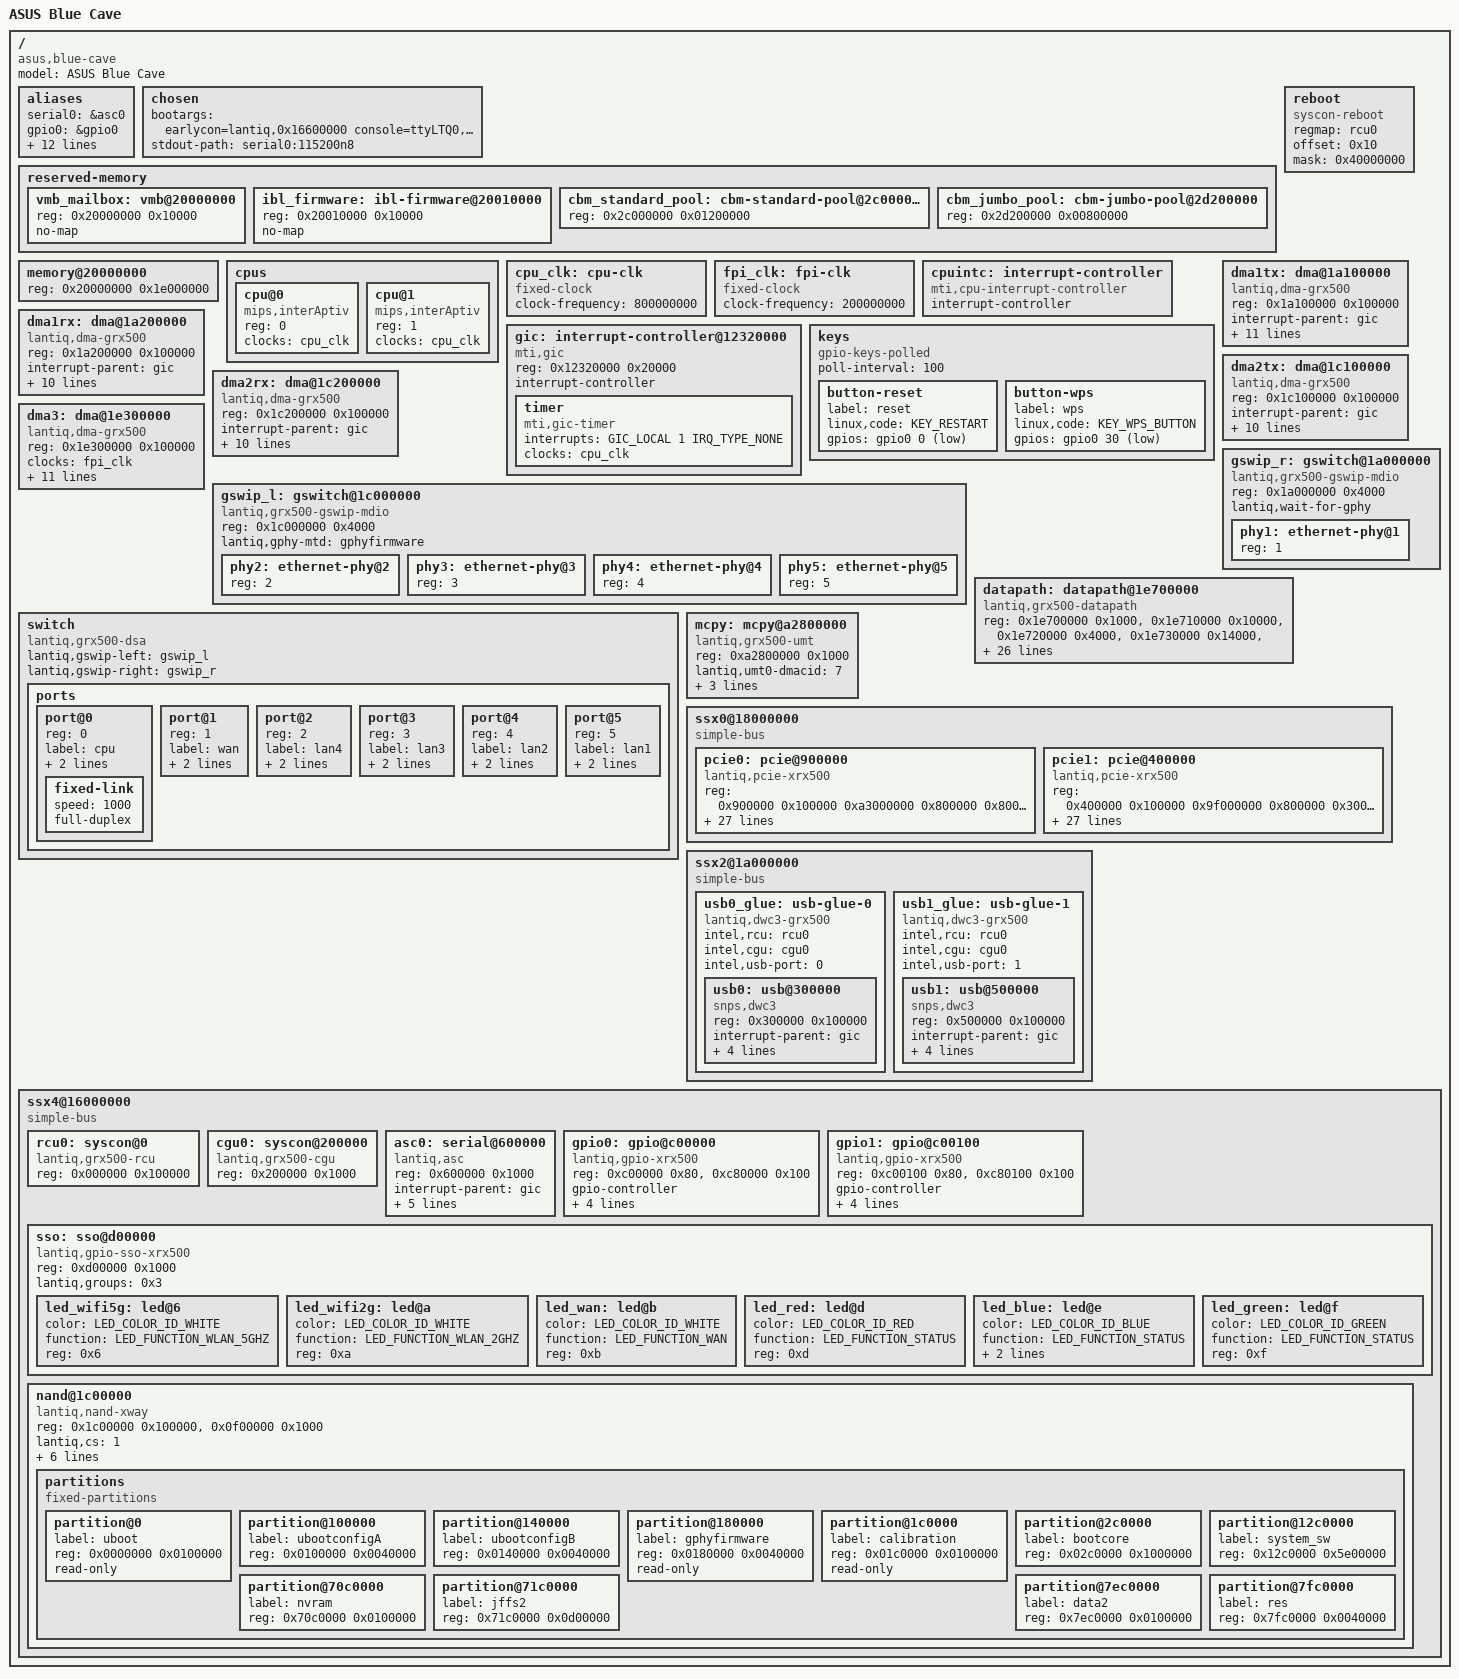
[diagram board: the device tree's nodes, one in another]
// SPDX-License-Identifier: GPL-2.0-or-later
/*
 * ASUS Blue Cave (Intel/Lantiq GRX350 / xRX500)
 * Stage-2 Bring-up DTS (Linux 6.18 + UART + Reboot + NAND 128MiB + USB 3.0 xHCI)
 */

/dts-v1/;

#include <dt-bindings/gpio/gpio.h>
#include <dt-bindings/input/input.h>
#include <dt-bindings/interrupt-controller/mips-gic.h>
#include <dt-bindings/leds/common.h>

/ {
	compatible = "asus,blue-cave", "intel,grx500", "lantiq,xrx500";
	model = "ASUS Blue Cave";
	#address-cells = <1>;
	#size-cells = <1>;

	aliases {
		serial0 = &asc0;
		gpio0 = &gpio0;
		gpio1 = &gpio1;
		dma1 = &dma1tx;
		dma2 = &dma1rx;
		dma3 = &dma2tx;
		dma4 = &dma2rx;
		dma5 = &dma3;
		pcie0 = &pcie0;
		pcie1 = &pcie1;
		led-boot = &led_blue;
		led-failsafe = &led_red;
		led-running = &led_blue;
		led-upgrade = &led_green;
	};

	chosen {
		bootargs = "earlycon=lantiq,0x16600000 console=ttyLTQ0,115200 clk_ignore_unused panic=5";
		stdout-path = "serial0:115200n8";
	};

	reserved-memory {
		#address-cells = <1>;
		#size-cells = <1>;
		ranges;

		vmb_mailbox: vmb@20000000 {
			reg = <0x20000000 0x10000>;
			no-map;
		};

		ibl_firmware: ibl-firmware@20010000 {
			reg = <0x20010000 0x10000>;
			no-map;
		};

		cbm_standard_pool: cbm-standard-pool@2c000000 {
			reg = <0x2c000000 0x01200000>;
		};

		cbm_jumbo_pool: cbm-jumbo-pool@2d200000 {
			reg = <0x2d200000 0x00800000>;
		};
	};

	/*
	 * GRX350 physical DRAM: 480 MiB (0x1e000000) @ 0x20000000 via EVA 1GB
	 */
	memory@20000000 {
		device_type = "memory";
		reg = <0x20000000 0x1e000000>;
	};

	cpus {
		#address-cells = <1>;
		#size-cells = <0>;

		cpu@0 {
			device_type = "cpu";
			compatible = "mips,interAptiv";
			reg = <0>;
			clocks = <&cpu_clk>;
		};

		cpu@1 {
			device_type = "cpu";
			compatible = "mips,interAptiv";
			reg = <1>;
			clocks = <&cpu_clk>;
		};
	};

	cpu_clk: cpu-clk {
		compatible = "fixed-clock";
		#clock-cells = <0>;
		clock-frequency = <800000000>;
	};

	fpi_clk: fpi-clk {
		compatible = "fixed-clock";
		#clock-cells = <0>;
		clock-frequency = <200000000>;
	};

	cpuintc: interrupt-controller {
		#interrupt-cells = <1>;
		interrupt-controller;
		compatible = "mti,cpu-interrupt-controller";
	};

	gic: interrupt-controller@12320000 {
		compatible = "mti,gic";
		reg = <0x12320000 0x20000>;

		interrupt-controller;
		#interrupt-cells = <3>;

		timer {
			compatible = "mti,gic-timer";
			interrupts = <GIC_LOCAL 1 IRQ_TYPE_NONE>;
			clocks = <&cpu_clk>;
		};
	};

	reboot {
		compatible = "syscon-reboot";
		regmap = <&rcu0>;
		offset = <0x10>;
		mask = <0x40000000>;
	};

	keys {
		compatible = "gpio-keys-polled";
		poll-interval = <100>;

		button-reset {
			label = "reset";
			linux,code = <KEY_RESTART>;
			gpios = <&gpio0 0 GPIO_ACTIVE_LOW>;
		};

		button-wps {
			label = "wps";
			linux,code = <KEY_WPS_BUTTON>;
			gpios = <&gpio0 30 GPIO_ACTIVE_LOW>;
		};
	};

	/* GRX350/GRX500 DMA controllers for GSWIP-L/R & CBM */
	dma1tx: dma@1a100000 {
		compatible = "lantiq,dma-grx500";
		reg = <0x1a100000 0x100000>;
		interrupt-parent = <&gic>;
		interrupts = <GIC_SHARED 65 IRQ_TYPE_LEVEL_HIGH>;
		lantiq,dma-pkt-arb = <2>;
		lantiq,dma-burst = <16>;
		lantiq,dma-polling-cnt = <108>;
		lantiq,dma-chan-fc = <1>;
		lantiq,dma-desc-fod = <1>;
		lantiq,dma-desc-in-sram = <1>;
		lantiq,dma-drb = <0>;
		lantiq,dma-byte-en = <1>;
		lantiq,budget = <20>;
		lantiq,dma-lab-cnt = <2>;
		status = "okay";
	};

	dma1rx: dma@1a200000 {
		compatible = "lantiq,dma-grx500";
		reg = <0x1a200000 0x100000>;
		interrupt-parent = <&gic>;
		interrupts = <GIC_SHARED 66 IRQ_TYPE_LEVEL_HIGH>;
		lantiq,dma-pkt-arb = <2>;
		lantiq,dma-burst = <16>;
		lantiq,dma-polling-cnt = <24>;
		lantiq,dma-chan-fc = <0>;
		lantiq,dma-desc-fod = <1>;
		lantiq,dma-desc-in-sram = <0>;
		lantiq,dma-drb = <0>;
		lantiq,dma-byte-en = <0>;
		lantiq,budget = <20>;
		status = "okay";
	};

	dma2tx: dma@1c100000 {
		compatible = "lantiq,dma-grx500";
		reg = <0x1c100000 0x100000>;
		interrupt-parent = <&gic>;
		interrupts = <GIC_SHARED 67 IRQ_TYPE_LEVEL_HIGH>;
		lantiq,dma-pkt-arb = <2>;
		lantiq,dma-burst = <16>;
		lantiq,dma-polling-cnt = <24>;
		lantiq,dma-chan-fc = <1>;
		lantiq,dma-desc-fod = <1>;
		lantiq,dma-desc-in-sram = <0>;
		lantiq,dma-drb = <0>;
		lantiq,dma-byte-en = <1>;
		lantiq,budget = <20>;
		status = "okay";
	};

	dma2rx: dma@1c200000 {
		compatible = "lantiq,dma-grx500";
		reg = <0x1c200000 0x100000>;
		interrupt-parent = <&gic>;
		interrupts = <GIC_SHARED 68 IRQ_TYPE_LEVEL_HIGH>;
		lantiq,dma-pkt-arb = <2>;
		lantiq,dma-burst = <16>;
		lantiq,dma-polling-cnt = <24>;
		lantiq,dma-chan-fc = <0>;
		lantiq,dma-desc-fod = <1>;
		lantiq,dma-desc-in-sram = <1>;
		lantiq,dma-drb = <0>;
		lantiq,dma-byte-en = <1>;
		lantiq,budget = <20>;
		status = "okay";
	};

	dma3: dma@1e300000 {
		compatible = "lantiq,dma-grx500";
		reg = <0x1e300000 0x100000>;
		clocks = <&fpi_clk>;
		interrupt-parent = <&gic>;
		interrupts = <GIC_SHARED 77 IRQ_TYPE_LEVEL_HIGH>;
		lantiq,dma-pkt-arb = <2>;
		lantiq,dma-burst = <16>;
		lantiq,dma-polling-cnt = <24>;
		lantiq,dma-chan-fc = <0>;
		lantiq,dma-desc-fod = <0>;
		lantiq,dma-desc-in-sram = <1>;
		lantiq,dma-drb = <0>;
		lantiq,dma-byte-en = <1>;
		lantiq,budget = <20>;
		status = "okay";
	};

	/* GSWIP-L MDIO (loads GPHY FW directly from factory NAND mtd3 at runtime) */
	gswip_l: gswitch@1c000000 {
		compatible = "lantiq,grx500-gswip-mdio";
		reg = <0x1c000000 0x4000>;
		lantiq,gphy-mtd = "gphyfirmware";
		#address-cells = <1>;
		#size-cells = <0>;

		phy2: ethernet-phy@2 { reg = <2>; };
		phy3: ethernet-phy@3 { reg = <3>; };
		phy4: ethernet-phy@4 { reg = <4>; };
		phy5: ethernet-phy@5 { reg = <5>; };
	};

	/* GSWIP-R MDIO (WAN port) */
	gswip_r: gswitch@1a000000 {
		compatible = "lantiq,grx500-gswip-mdio";
		reg = <0x1a000000 0x4000>;
		lantiq,wait-for-gphy;
		#address-cells = <1>;
		#size-cells = <0>;

		phy1: ethernet-phy@1 { reg = <1>; };
	};

	datapath: datapath@1e700000 {
		compatible = "lantiq,grx500-datapath";
		reg = <0x1e700000 0x1000>,
		      <0x1e710000 0x10000>,
		      <0x1e720000 0x4000>,
		      <0x1e730000 0x14000>,
		      <0x1e750000 0x400>,
		      <0x1e750800 0x400>,
		      <0x1e760000 0x10000>,
		      <0x1e780000 0x20000>,
		      <0x1e7c0000 0x30000>,
		      <0x1e800000 0x100000>,
		      <0x1e900000 0x100000>,
		      <0x1e500000 0x100000>;
		reg-names = "tmu", "cbm", "qidt", "sbim", "qeqcnt",
			    "qdqcnt", "ls", "eqm", "dqm", "fsqm0",
			    "fsqm1", "dma-desc";
		interrupt-parent = <&gic>;
		interrupts = <GIC_SHARED 174 IRQ_TYPE_LEVEL_HIGH>,
			     <GIC_SHARED 178 IRQ_TYPE_LEVEL_HIGH>,
			     <GIC_SHARED 179 IRQ_TYPE_LEVEL_HIGH>,
			     <GIC_SHARED 180 IRQ_TYPE_LEVEL_HIGH>,
			     <GIC_SHARED 181 IRQ_TYPE_LEVEL_HIGH>;
		interrupt-names = "eqm", "dqm-cpu0", "dqm-cpu1",
				  "dqm-cpu2", "dqm-cpu3";
		lantiq,gswip-left = <&gswip_l>;
		lantiq,gswip-right = <&gswip_r>;
		memory-region = <&cbm_standard_pool>, <&cbm_jumbo_pool>;
		memory-region-names = "standard", "jumbo";
		lantiq,lan-eqm-routes = <5 2 14 0 2>, <5 2 30 1 2>,
				 <6 2 15 0 2>, <6 2 31 1 2>;
		lantiq,gswr-eqm-route = <7 1 0 0 2>;
		lantiq,lan-dqm-routes = <6 16 2 1 2>, <7 17 2 2 2>,
				 <8 18 2 3 2>, <9 19 2 4 2>,
				 <10 20 2 5 2>, <11 21 2 6 2>,
				 <12 22 2 9 2>, <13 23 2 10 2>,
				 <14 24 2 11 2>, <15 25 2 12 2>,
				 <16 26 2 13 2>, <17 27 2 14 2>;
		lantiq,wan-dqm-route = <19 28 1 15 2>;
		lantiq,cpu-dqm-port = <2 35>;
	};

	switch {
		compatible = "lantiq,grx500-dsa";
		lantiq,gswip-left = <&gswip_l>;
		lantiq,gswip-right = <&gswip_r>;

		ports {
			#address-cells = <1>;
			#size-cells = <0>;

			port@0 {
				reg = <0>;
				label = "cpu";
				ethernet = <&datapath>;
				phy-mode = "internal";

				fixed-link {
					speed = <1000>;
					full-duplex;
				};
			};

			port@1 {
				reg = <1>;
				label = "wan";
				phy-mode = "rgmii";
				phy-handle = <&phy1>;
			};

			port@2 {
				reg = <2>;
				label = "lan4";
				phy-mode = "gmii";
				phy-handle = <&phy2>;
			};

			port@3 {
				reg = <3>;
				label = "lan3";
				phy-mode = "gmii";
				phy-handle = <&phy3>;
			};

			port@4 {
				reg = <4>;
				label = "lan2";
				phy-mode = "gmii";
				phy-handle = <&phy4>;
			};

			port@5 {
				reg = <5>;
				label = "lan1";
				phy-mode = "gmii";
				phy-handle = <&phy5>;
			};
		};
	};

	mcpy: mcpy@a2800000 {
		compatible = "lantiq,grx500-umt";
		reg = <0xa2800000 0x1000>;
		lantiq,umt0-dmacid = <7>;
		lantiq,umt1-dmacid = <8>;
		lantiq,umt2-dmacid = <9>;
		lantiq,umt3-dmacid = <10>;
	};

	/* SSX0: PCIe Root Complexes (pcie0 & pcie1 for WAV514/524 dual Wi-Fi) */
	ssx0@18000000 {
		compatible = "simple-bus";
		#address-cells = <1>;
		#size-cells = <1>;
		ranges = <0x0 0x18000000 0xa8000000>;

		pcie0: pcie@900000 {
			compatible = "lantiq,pcie-xrx500";
			device_type = "pci";
			#address-cells = <3>;
			#size-cells = <2>;
			reg = <
				0x900000 0x100000
				0xa3000000 0x800000
				0x800000 0x100000
				0x500000 0x100000
				0x600000 0x100000
				0x700000 0x100000
			>;
			reg-names = "csr", "cfg", "app", "phy", "msi", "pic";
			interrupt-parent = <&gic>;
			interrupt-controller;
			interrupts = <GIC_SHARED 128 IRQ_TYPE_EDGE_RISING>,
				     <GIC_SHARED 129 IRQ_TYPE_EDGE_RISING>,
				     <GIC_SHARED 130 IRQ_TYPE_EDGE_RISING>,
				     <GIC_SHARED 131 IRQ_TYPE_EDGE_RISING>,
				     <GIC_SHARED 132 IRQ_TYPE_EDGE_RISING>,
				     <GIC_SHARED 133 IRQ_TYPE_EDGE_RISING>,
				     <GIC_SHARED 134 IRQ_TYPE_EDGE_RISING>,
				     <GIC_SHARED 135 IRQ_TYPE_EDGE_RISING>,
				     <GIC_SHARED 152 IRQ_TYPE_LEVEL_HIGH>,
				     <GIC_SHARED 136 IRQ_TYPE_LEVEL_HIGH>,
				     <GIC_SHARED 137 IRQ_TYPE_LEVEL_HIGH>,
				     <GIC_SHARED 138 IRQ_TYPE_LEVEL_HIGH>,
				     <GIC_SHARED 139 IRQ_TYPE_LEVEL_HIGH>;
			interrupt-names = "msi0", "msi1", "msi2", "msi3",
					  "msi4", "msi5", "msi6", "msi7",
					  "ir", "inta", "intb", "intc", "intd";
			#interrupt-cells = <1>;
			interrupt-map-mask = <0 0 0 0x7>;
			interrupt-map = <0 0 0 1 &pcie0 0>,
					<0 0 0 2 &pcie0 1>,
					<0 0 0 3 &pcie0 2>,
					<0 0 0 4 &pcie0 3>;
			ranges = <0x02000000 0 0xa0000000 0xa0000000 0 0x03000000
				  0x01000000 0 0xa3800000 0xa3800000 0 0x00100000>;
			reset-gpio = <&gpio0 18 GPIO_ACTIVE_LOW>;
			lantiq,rst-high-active = <0>;
			lantiq,rst-interval = <200>;
			lantiq,inbound-swap = <1>;
			lantiq,inbound-shift = <5>;
			lantiq,outbound-swap = <0>;
			lantiq,outbound-shift = <4>;
			lantiq,clkout = <22>;
			status = "okay";
		};

		pcie1: pcie@400000 {
			compatible = "lantiq,pcie-xrx500";
			device_type = "pci";
			#address-cells = <3>;
			#size-cells = <2>;
			reg = <
				0x400000 0x100000
				0x9f000000 0x800000
				0x300000 0x100000
				0x000000 0x100000
				0x100000 0x100000
				0x200000 0x100000
			>;
			reg-names = "csr", "cfg", "app", "phy", "msi", "pic";
			interrupt-parent = <&gic>;
			interrupt-controller;
			interrupts = <GIC_SHARED 37 IRQ_TYPE_EDGE_RISING>,
				     <GIC_SHARED 38 IRQ_TYPE_EDGE_RISING>,
				     <GIC_SHARED 39 IRQ_TYPE_EDGE_RISING>,
				     <GIC_SHARED 40 IRQ_TYPE_EDGE_RISING>,
				     <GIC_SHARED 41 IRQ_TYPE_EDGE_RISING>,
				     <GIC_SHARED 42 IRQ_TYPE_EDGE_RISING>,
				     <GIC_SHARED 43 IRQ_TYPE_EDGE_RISING>,
				     <GIC_SHARED 44 IRQ_TYPE_EDGE_RISING>,
				     <GIC_SHARED 49 IRQ_TYPE_LEVEL_HIGH>,
				     <GIC_SHARED 9 IRQ_TYPE_LEVEL_HIGH>,
				     <GIC_SHARED 10 IRQ_TYPE_LEVEL_HIGH>,
				     <GIC_SHARED 11 IRQ_TYPE_LEVEL_HIGH>,
				     <GIC_SHARED 12 IRQ_TYPE_LEVEL_HIGH>;
			interrupt-names = "msi0", "msi1", "msi2", "msi3",
					  "msi4", "msi5", "msi6", "msi7",
					  "ir", "inta", "intb", "intc", "intd";
			#interrupt-cells = <1>;
			interrupt-map-mask = <0 0 0 0x7>;
			interrupt-map = <0 0 0 1 &pcie1 0>,
					<0 0 0 2 &pcie1 1>,
					<0 0 0 3 &pcie1 2>,
					<0 0 0 4 &pcie1 3>;
			ranges = <0x02000000 0 0x9c000000 0x9c000000 0 0x03000000
				  0x01000000 0 0x9f800000 0x9f800000 0 0x00100000>;
			reset-gpio = <&gpio0 17 GPIO_ACTIVE_LOW>;
			lantiq,rst-high-active = <0>;
			lantiq,rst-interval = <200>;
			lantiq,inbound-swap = <1>;
			lantiq,inbound-shift = <9>;
			lantiq,outbound-swap = <0>;
			lantiq,outbound-shift = <8>;
			lantiq,clkout = <23>;
			status = "okay";
		};
	};

	/* SSX2: USB 3.0 DWC3 controllers (0x1a000000) */
	ssx2@1a000000 {
		compatible = "simple-bus";
		#address-cells = <1>;
		#size-cells = <1>;
		ranges = <0x0 0x1a000000 0x02000000>;

		usb0_glue: usb-glue-0 {
			compatible = "lantiq,dwc3-grx500";
			#address-cells = <1>;
			#size-cells = <1>;
			ranges;
			intel,rcu = <&rcu0>;
			intel,cgu = <&cgu0>;
			intel,usb-port = <0>;

			usb0: usb@300000 {
				compatible = "snps,dwc3";
				reg = <0x300000 0x100000>;
				interrupt-parent = <&gic>;
				interrupts = <GIC_SHARED 54 IRQ_TYPE_LEVEL_HIGH>;
				dr_mode = "host";
				snps,dis_u2_susphy_quirk;
				snps,dis_u3_susphy_quirk;
			};
		};

		usb1_glue: usb-glue-1 {
			compatible = "lantiq,dwc3-grx500";
			#address-cells = <1>;
			#size-cells = <1>;
			ranges;
			intel,rcu = <&rcu0>;
			intel,cgu = <&cgu0>;
			intel,usb-port = <1>;

			usb1: usb@500000 {
				compatible = "snps,dwc3";
				reg = <0x500000 0x100000>;
				interrupt-parent = <&gic>;
				interrupts = <GIC_SHARED 83 IRQ_TYPE_LEVEL_HIGH>;
				dr_mode = "host";
				snps,dis_u2_susphy_quirk;
				snps,dis_u3_susphy_quirk;
			};
		};
	};

	/* SSX4: RCU / UART / EBU NAND (0x16000000) */
	ssx4@16000000 {
		compatible = "simple-bus";
		#address-cells = <1>;
		#size-cells = <1>;
		ranges = <0x0 0x16000000 0x02000000>;

		/* RCU (0x16000000) + CHIPTOP (0x16080000) */
		rcu0: syscon@0 {
			compatible = "lantiq,grx500-rcu", "syscon";
			reg = <0x000000 0x100000>;
		};

		/* CGU (0x16200000) */
		cgu0: syscon@200000 {
			compatible = "lantiq,grx500-cgu", "syscon";
			reg = <0x200000 0x1000>;
		};

		asc0: serial@600000 {
			compatible = "lantiq,asc";
			reg = <0x600000 0x1000>;
			interrupt-parent = <&gic>;
			interrupts = <GIC_SHARED 103 IRQ_TYPE_LEVEL_HIGH>,
				     <GIC_SHARED 105 IRQ_TYPE_LEVEL_HIGH>,
				     <GIC_SHARED 106 IRQ_TYPE_LEVEL_HIGH>;
			clocks = <&fpi_clk>, <&fpi_clk>;
			clock-names = "freq", "asc";
			status = "okay";
		};

		gpio0: gpio@c00000 {
			compatible = "lantiq,gpio-xrx500", "lantiq,grx500-gpio";
			reg = <0xc00000 0x80>,
			      <0xc80000 0x100>;
			gpio-controller;
			#gpio-cells = <2>;
			interrupt-controller;
			#interrupt-cells = <2>;
			interrupt-parent = <&gic>;
			interrupts = <GIC_SHARED 172 IRQ_TYPE_LEVEL_HIGH>;
			lantiq,bank = <0>;
		};

		gpio1: gpio@c00100 {
			compatible = "lantiq,gpio-xrx500", "lantiq,grx500-gpio";
			reg = <0xc00100 0x80>,
			      <0xc80100 0x100>;
			gpio-controller;
			#gpio-cells = <2>;
			interrupt-controller;
			#interrupt-cells = <2>;
			interrupt-parent = <&gic>;
			interrupts = <GIC_SHARED 173 IRQ_TYPE_LEVEL_HIGH>;
			lantiq,bank = <1>;
		};

		sso: sso@d00000 {
			compatible = "lantiq,gpio-sso-xrx500";
			reg = <0xd00000 0x1000>;
			lantiq,groups = <0x3>;
			#address-cells = <1>;
			#size-cells = <0>;

			led_wifi5g: led@6 {
				color = <LED_COLOR_ID_WHITE>;
				function = LED_FUNCTION_WLAN_5GHZ;
				reg = <0x6>;
			};

			led_wifi2g: led@a {
				color = <LED_COLOR_ID_WHITE>;
				function = LED_FUNCTION_WLAN_2GHZ;
				reg = <0xa>;
			};

			led_wan: led@b {
				color = <LED_COLOR_ID_WHITE>;
				function = LED_FUNCTION_WAN;
				reg = <0xb>;
			};

			led_red: led@d {
				color = <LED_COLOR_ID_RED>;
				function = LED_FUNCTION_STATUS;
				reg = <0xd>;
			};

			led_blue: led@e {
				color = <LED_COLOR_ID_BLUE>;
				function = LED_FUNCTION_STATUS;
				reg = <0xe>;
				default-state = "on";
			};

			led_green: led@f {
				color = <LED_COLOR_ID_GREEN>;
				function = LED_FUNCTION_STATUS;
				reg = <0xf>;
			};
		};

		nand@1c00000 {
			compatible = "lantiq,nand-xway";
			reg = <0x1c00000 0x100000>,
			      <0x0f00000 0x1000>;
			lantiq,cs = <1>;
			bank-width = <2>;
			nand-on-flash-bbt;
			nand-ecc-engine = <0>;
			nand-ecc-algo = "bch";
			nand-ecc-strength = <4>;
			nand-ecc-step-size = <512>;

			partitions {
				compatible = "fixed-partitions";
				#address-cells = <1>;
				#size-cells = <1>;

				partition@0 {
					label = "uboot";
					reg = <0x0000000 0x0100000>;
					read-only;
				};

				partition@100000 {
					label = "ubootconfigA";
					reg = <0x0100000 0x0040000>;
				};

				partition@140000 {
					label = "ubootconfigB";
					reg = <0x0140000 0x0040000>;
				};

				partition@180000 {
					label = "gphyfirmware";
					reg = <0x0180000 0x0040000>;
					read-only;
				};

				partition@1c0000 {
					label = "calibration";
					reg = <0x01c0000 0x0100000>;
					read-only;
				};

				partition@2c0000 {
					label = "bootcore";
					reg = <0x02c0000 0x1000000>;
				};

				partition@12c0000 {
					label = "system_sw";
					reg = <0x12c0000 0x5e00000>;
				};

				partition@70c0000 {
					label = "nvram";
					reg = <0x70c0000 0x0100000>;
				};

				partition@71c0000 {
					label = "jffs2";
					reg = <0x71c0000 0x0d00000>;
				};

				partition@7ec0000 {
					label = "data2";
					reg = <0x7ec0000 0x0100000>;
				};

				partition@7fc0000 {
					label = "res";
					reg = <0x7fc0000 0x0040000>;
				};
			};
		};
	};
};
